AUTOSAR XML (schema 314)
package /ComponentType
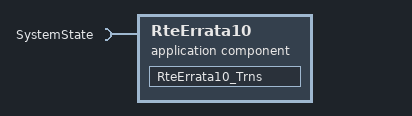
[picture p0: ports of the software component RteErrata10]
  application software component type RteErrata10  # This SWC contains definitions required to workaround Rte Generation errata following: 1) ESCAN00059438AN00059438 (corrected in Rte 2.22.00)
    require port SystemState: required-interface=SystemState
  internal behavior RteErrata10_InternalBehavior: component=RteErrata10, port-api-option{enable-take-address=false, indirect-api=false, port=SystemState}
    4 x mode switch event, all with start-on-event=RteErrata10_Trns, activation=ENTRY:
      MST_RteErrata10_Trns_0: mode=SystemState.Mode.OPERATE
      MST_RteErrata10_Trns_1: mode=SystemState.Mode.WARMINIT
      MST_RteErrata10_Trns_2: mode=SystemState.Mode.OFF
      MST_RteErrata10_Trns_3: mode=SystemState.Mode.DISABLE
    runnable RteErrata10_Trns
  swc implementation RteErrata10_Implementation: behavior=RteErrata10_InternalBehavior
    code-descriptors:
      code Code: type=SRC
